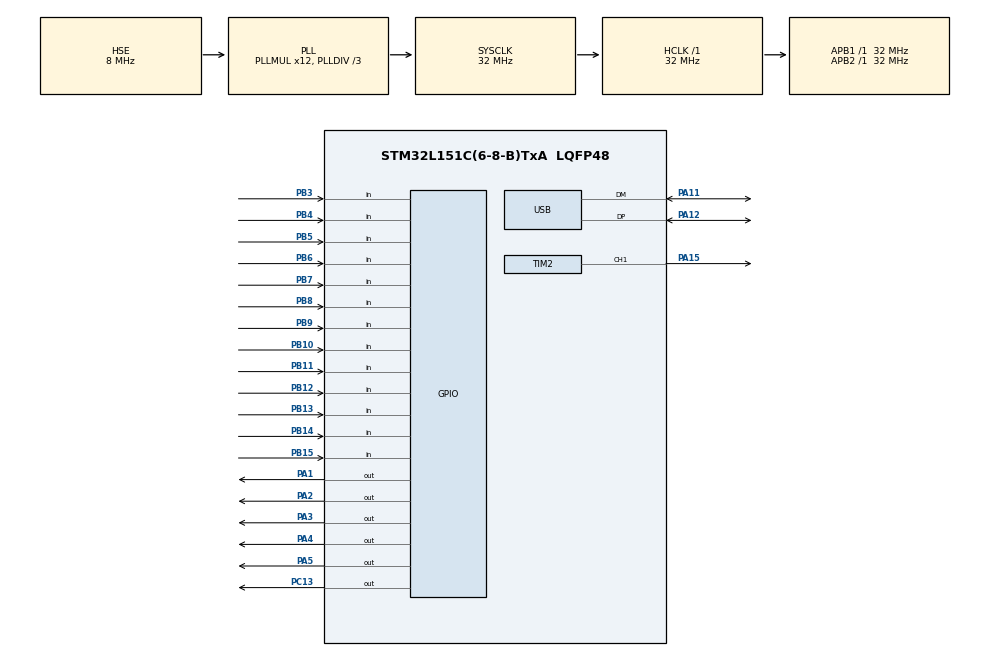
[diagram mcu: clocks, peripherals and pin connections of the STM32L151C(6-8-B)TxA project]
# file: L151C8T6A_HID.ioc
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Dma.Request0=TIM2_CH1
Dma.TIM2_CH1.0.Direction=DMA_MEMORY_TO_PERIPH
Dma.TIM2_CH1.0.Instance=DMA1_Channel5
Dma.TIM2_CH1.0.MemDataAlignment=DMA_MDATAALIGN_BYTE
Dma.TIM2_CH1.0.MemInc=DMA_MINC_ENABLE
Dma.TIM2_CH1.0.Mode=DMA_NORMAL
Dma.TIM2_CH1.0.PeriphDataAlignment=DMA_PDATAALIGN_BYTE
Dma.TIM2_CH1.0.PeriphInc=DMA_PINC_DISABLE
Dma.TIM2_CH1.0.Priority=DMA_PRIORITY_MEDIUM
Mcu.Family=STM32L1
Mcu.Name=STM32L151C(6-8-B)TxA
Mcu.Package=LQFP48
NVIC.DMA1_Channel5_IRQn=true\:0\:0\:false\:false\:true\:false\:true\:true
NVIC.PriorityGroup=NVIC_PRIORITYGROUP_4
NVIC.USB_LP_IRQn=true\:0\:0\:false\:false\:true\:false\:true\:true
PA1.GPIO_ModeDefaultOutputPP=GPIO_MODE_OUTPUT_OD
PA1.GPIO_PuPd=GPIO_NOPULL
PA1.PinState=GPIO_PIN_SET
PA1.Signal=GPIO_Output
PA11.Mode=Device
PA11.Signal=USB_DM
PA12.Mode=Device
PA12.Signal=USB_DP
PA13.Mode=Serial_Wire
PA13.Signal=SYS_JTMS-SWDIO
PA14.Mode=Serial_Wire
PA14.Signal=SYS_JTCK-SWCLK
PA15.Signal=S_TIM2_CH1_ETR
PA2.GPIO_ModeDefaultOutputPP=GPIO_MODE_OUTPUT_OD
PA2.GPIO_PuPd=GPIO_NOPULL
PA2.PinState=GPIO_PIN_SET
PA2.Signal=GPIO_Output
PA3.GPIO_ModeDefaultOutputPP=GPIO_MODE_OUTPUT_OD
PA3.GPIO_PuPd=GPIO_NOPULL
PA3.PinState=GPIO_PIN_SET
PA3.Signal=GPIO_Output
PA4.GPIO_ModeDefaultOutputPP=GPIO_MODE_OUTPUT_OD
PA4.GPIO_PuPd=GPIO_NOPULL
PA4.PinState=GPIO_PIN_SET
PA4.Signal=GPIO_Output
PA5.GPIO_ModeDefaultOutputPP=GPIO_MODE_OUTPUT_OD
PA5.GPIO_PuPd=GPIO_NOPULL
PA5.PinState=GPIO_PIN_SET
PA5.Signal=GPIO_Output
PB10.GPIO_Mode=GPIO_MODE_INPUT
PB10.GPIO_PuPd=GPIO_PULLUP
PB10.Signal=GPIO_Input
PB11.GPIO_Mode=GPIO_MODE_INPUT
PB11.GPIO_PuPd=GPIO_PULLUP
PB11.Signal=GPIO_Input
PB12.GPIO_Mode=GPIO_MODE_INPUT
PB12.GPIO_PuPd=GPIO_PULLUP
PB12.Signal=GPIO_Input
PB13.GPIO_Mode=GPIO_MODE_INPUT
PB13.GPIO_PuPd=GPIO_PULLUP
PB13.Signal=GPIO_Input
PB14.GPIO_Mode=GPIO_MODE_INPUT
PB14.GPIO_PuPd=GPIO_PULLUP
PB14.Signal=GPIO_Input
PB15.GPIO_Mode=GPIO_MODE_INPUT
PB15.GPIO_PuPd=GPIO_PULLUP
PB15.Signal=GPIO_Input
PB3.GPIO_Mode=GPIO_MODE_INPUT
PB3.GPIO_PuPd=GPIO_PULLUP
PB3.Signal=GPIO_Input
PB4.GPIO_Mode=GPIO_MODE_INPUT
PB4.GPIO_PuPd=GPIO_PULLUP
PB4.Signal=GPIO_Input
PB5.GPIO_Mode=GPIO_MODE_INPUT
PB5.GPIO_PuPd=GPIO_PULLUP
PB5.Signal=GPIO_Input
PB6.GPIO_Mode=GPIO_MODE_INPUT
PB6.GPIO_PuPd=GPIO_PULLUP
PB6.Signal=GPIO_Input
PB7.GPIO_Mode=GPIO_MODE_INPUT
PB7.GPIO_PuPd=GPIO_PULLUP
PB7.Signal=GPIO_Input
PB8.GPIO_Mode=GPIO_MODE_INPUT
PB8.GPIO_PuPd=GPIO_PULLUP
PB8.Signal=GPIO_Input
PB9.GPIO_Mode=GPIO_MODE_INPUT
PB9.GPIO_PuPd=GPIO_PULLUP
PB9.Signal=GPIO_Input
PC13-WKUP2.GPIO_Speed=GPIO_SPEED_FREQ_MEDIUM
PC13-WKUP2.PinState=GPIO_PIN_SET
PC13-WKUP2.Signal=GPIO_Output
PC14-OSC32_IN.Mode=LSE-External-Oscillator
PC14-OSC32_IN.Signal=RCC_OSC32_IN
PC15-OSC32_OUT.Mode=LSE-External-Oscillator
PC15-OSC32_OUT.Signal=RCC_OSC32_OUT
PH0-OSC_IN.Mode=HSE-External-Oscillator
PH0-OSC_IN.Signal=RCC_OSC_IN
PH1-OSC_OUT.Mode=HSE-External-Oscillator
PH1-OSC_OUT.Signal=RCC_OSC_OUT
ProjectManager.HeapSize=0x800
ProjectManager.StackSize=0x1000
ProjectManager.TargetToolchain=STM32CubeIDE
RCC.48MHZClocksFreq_Value=48000000
RCC.AHBFreq_Value=32000000
RCC.APB1Freq_Value=32000000
RCC.APB1TimFreq_Value=32000000
RCC.APB2Freq_Value=32000000
RCC.APB2TimFreq_Value=32000000
RCC.HCLKFreq_Value=32000000
RCC.HSE_VALUE=8000000
RCC.HSI_VALUE=16000000
RCC.MSI_VALUE=2097000
RCC.PLLDIV=RCC_PLL_DIV3
RCC.PLLMUL=RCC_PLL_MUL12
RCC.SYSCLKFreq_VALUE=32000000
RCC.SYSCLKSource=RCC_SYSCLKSOURCE_PLLCLK
RCC.VCOOutputFreq_Value=96000000
SH.S_TIM2_CH1_ETR.0=TIM2_CH1,PWM Generation1 CH1
TIM2.Channel-PWM\ Generation1\ CH1=TIM_CHANNEL_1
TIM2.Period=39
USB_DEVICE.CLASS_NAME_FS=CUSTOM_HID
USB_DEVICE.CUSTOM_HID_FS_BINTERVAL=0x1
USB_DEVICE.MANUFACTURER_STRING=zian1
USB_DEVICE.PID_CUSTOMHID_FS=0xC8F8
USB_DEVICE.PRODUCT_STRING_CUSTOMHID_FS=stm32_keyboard
USB_DEVICE.USBD_CUSTOM_HID_REPORT_DESC_SIZE=3
USB_DEVICE.USBD_MAX_NUM_INTERFACES=3
USB_DEVICE.USBD_MAX_STR_DESC_SIZ=64
USB_DEVICE.USBD_SELF_POWERED=0
USB_DEVICE.VID=0x151A
USB_DEVICE.VirtualMode=CustomHid
USB_DEVICE.VirtualModeFS=Custom_Hid_FS
VP_TIM2_VS_ClockSourceINT.Mode=Internal
VP_USB_DEVICE_VS_USB_DEVICE_CUSTOM_HID_FS.Mode=CUSTOM_HID_FS
board=custom

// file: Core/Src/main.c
/* USER CODE BEGIN Header */
/**
  ******************************************************************************
  * @file           : main.c
  * @brief          : Main program body
  ******************************************************************************
  * @attention
  *
  * Copyright (c) 2022 STMicroelectronics.
  * All rights reserved.
  *
  * This software is licensed under terms that can be found in the LICENSE file
  * in the root directory of this software component.
  * If no LICENSE file comes with this software, it is provided AS-IS.
  *
  ******************************************************************************
  */
/* USER CODE END Header */
#include "main.h"
#include "dma.h"
#include "tim.h"
#include "usb_device.h"
#include "gpio.h"

/* USER CODE BEGIN Includes */
#include "Functions.h"
/* USER CODE END Includes */

void SystemClock_Config(void);

int main(void)
{

  /* MCU Configuration--------------------------------------------------------*/

  /* Reset of all peripherals, Initializes the Flash interface and the Systick. */
  HAL_Init();

  /* Configure the system clock */
  SystemClock_Config();

  /* Initialize all configured peripherals */
  MX_GPIO_Init();
  MX_DMA_Init();
  MX_TIM2_Init();
  MX_USB_DEVICE_Init();

  /* Infinite loop */
  while (1)
  {

    /* USER CODE BEGIN 3 */
	  init_Main();
	  //HAL_GPIO_TogglePin(GPIOC, GPIO_PIN_13);
	 // HAL_Delay(1500);
  }
  /* USER CODE END 3 */
}

void SystemClock_Config(void)
{
  RCC_OscInitTypeDef RCC_OscInitStruct = {0};
  RCC_ClkInitTypeDef RCC_ClkInitStruct = {0};

  /** Configure the main internal regulator output voltage
  */
  __HAL_PWR_VOLTAGESCALING_CONFIG(PWR_REGULATOR_VOLTAGE_SCALE1);

  /** Initializes the RCC Oscillators according to the specified parameters
  * in the RCC_OscInitTypeDef structure.
  */
  RCC_OscInitStruct.OscillatorType = RCC_OSCILLATORTYPE_HSE;
  RCC_OscInitStruct.HSEState = RCC_HSE_ON;
  RCC_OscInitStruct.PLL.PLLState = RCC_PLL_ON;
  RCC_OscInitStruct.PLL.PLLSource = RCC_PLLSOURCE_HSE;
  RCC_OscInitStruct.PLL.PLLMUL = RCC_PLL_MUL12;
  RCC_OscInitStruct.PLL.PLLDIV = RCC_PLL_DIV3;
  if (HAL_RCC_OscConfig(&RCC_OscInitStruct) != HAL_OK)
  {
    Error_Handler();
  }

  /** Initializes the CPU, AHB and APB buses clocks
  */
  RCC_ClkInitStruct.ClockType = RCC_CLOCKTYPE_HCLK|RCC_CLOCKTYPE_SYSCLK
                              |RCC_CLOCKTYPE_PCLK1|RCC_CLOCKTYPE_PCLK2;
  RCC_ClkInitStruct.SYSCLKSource = RCC_SYSCLKSOURCE_PLLCLK;
  RCC_ClkInitStruct.AHBCLKDivider = RCC_SYSCLK_DIV1;
  RCC_ClkInitStruct.APB1CLKDivider = RCC_HCLK_DIV1;
  RCC_ClkInitStruct.APB2CLKDivider = RCC_HCLK_DIV1;

  if (HAL_RCC_ClockConfig(&RCC_ClkInitStruct, FLASH_LATENCY_1) != HAL_OK)
  {
    Error_Handler();
  }
}

void Error_Handler(void)
{
  __disable_irq();
  while (1)
  {
  }
}
